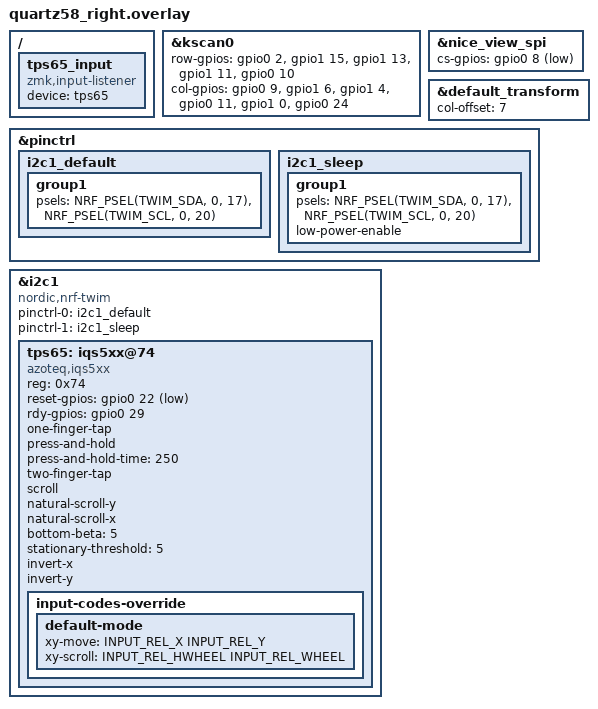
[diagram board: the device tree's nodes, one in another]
/*
 * Copyright (c) 2020 Pete Johanson
 *
 * SPDX-License-Identifier: MIT
 */

#include <dt-bindings/zmk/matrix_transform.h>
#include <dt-bindings/input/input-event-codes.h>
#include "quartz58.dtsi"

&kscan0 {
    row-gpios
        = <&gpio0 2  (GPIO_ACTIVE_HIGH | GPIO_PULL_DOWN)>
        , <&gpio1 15  (GPIO_ACTIVE_HIGH | GPIO_PULL_DOWN)>
        , <&gpio1 13 (GPIO_ACTIVE_HIGH | GPIO_PULL_DOWN)>
        , <&gpio1 11 (GPIO_ACTIVE_HIGH | GPIO_PULL_DOWN)>
        , <&gpio0 10 (GPIO_ACTIVE_HIGH | GPIO_PULL_DOWN)>
    ;

    col-gpios
        = <&gpio0 9  GPIO_ACTIVE_HIGH>
        , <&gpio1 6  GPIO_ACTIVE_HIGH>
        , <&gpio1 4  GPIO_ACTIVE_HIGH>
        , <&gpio0 11 GPIO_ACTIVE_HIGH>
        , <&gpio1 0  GPIO_ACTIVE_HIGH>
        , <&gpio0 24 GPIO_ACTIVE_HIGH>
    ;
};

&nice_view_spi {
    cs-gpios = <&gpio0 8 GPIO_ACTIVE_LOW>;
};

&default_transform {
    col-offset = <7>;
};

/ {

    // TPS65 trackpad input listener (right side only)
    tps65_input: tps65_input {
        compatible = "zmk,input-listener";
        device = <&tps65>;
    };
    
//     physical_layout0: physical_layout_0 {
//         compatible = "zmk,physical-layout";
//         display-name = "quartz58_right";
//         transform = <&default_transform>;
//         kscan = <&kscan0>;
//         keys  //                     w   h    x    y     rot    rx    ry
//             = <&key_physical_attrs 100 100  100    0       0     0     0>
//             , <&key_physical_attrs 100 100  200    0       0     0     0>
//             , <&key_physical_attrs 100 100  300    0       0     0     0>
//             , <&key_physical_attrs 100 100  400    0       0     0     0>
//             , <&key_physical_attrs 100 100  500    0       0     0     0>
//             , <&key_physical_attrs 100 100  600    0       0     0     0>
//             , <&key_physical_attrs 100 100  100  100       0     0     0>
//             , <&key_physical_attrs 100 100  200  100       0     0     0>
//             , <&key_physical_attrs 100 100  300  100       0     0     0>
//             , <&key_physical_attrs 100 100  400  100       0     0     0>
//             , <&key_physical_attrs 100 100  500  100       0     0     0>
//             , <&key_physical_attrs 100 100  600  100       0     0     0>
//             , <&key_physical_attrs 100 100    0  200       0     0     0>
//             , <&key_physical_attrs 100 100  100  200       0     0     0>
//             , <&key_physical_attrs 100 100  200  200       0     0     0>
//             , <&key_physical_attrs 100 100  300  200       0     0     0>
//             , <&key_physical_attrs 100 100  400  200       0     0     0>
//             , <&key_physical_attrs 100 100  500  200       0     0     0>
//             , <&key_physical_attrs 100 100  600  200       0     0     0>
//             , <&key_physical_attrs 100 100  100  300       0     0     0>
//             , <&key_physical_attrs 100 100  200  300       0     0     0>
//             , <&key_physical_attrs 100 100  300  300       0     0     0>
//             , <&key_physical_attrs 100 100  400  300       0     0     0>
//             , <&key_physical_attrs 100 100  500  300       0     0     0>
//             , <&key_physical_attrs 100 100  600  300       0     0     0>
//             , <&key_physical_attrs 100 100  100  400       0     0     0>
//             , <&key_physical_attrs 100 100  200  400       0     0     0>
//             , <&key_physical_attrs 100 100  300  400       0     0     0>
//             , <&key_physical_attrs 100 100  400  400       0     0     0>
//             ;
//     };
};

// Configure I2C1 on actual trackpad pins (P0.17=SDA, P0.20=SCL)
&pinctrl {
    i2c1_default: i2c1_default {
        group1 {
            psels = <NRF_PSEL(TWIM_SDA, 0, 17)>,
                    <NRF_PSEL(TWIM_SCL, 0, 20)>;
        };
    };

    i2c1_sleep: i2c1_sleep {
        group1 {
            psels = <NRF_PSEL(TWIM_SDA, 0, 17)>,
                    <NRF_PSEL(TWIM_SCL, 0, 20)>;
            low-power-enable;
        };
    };
};

// TPS65 trackpad on I2C1 (serial pins)
&i2c1 {
    status = "okay";
    compatible = "nordic,nrf-twim";
    pinctrl-0 = <&i2c1_default>;
    pinctrl-1 = <&i2c1_sleep>;
    pinctrl-names = "default", "sleep";
    
    tps65: iqs5xx@74 {
        status = "okay";
        compatible = "azoteq,iqs5xx";
        reg = <0x74>;
        
        reset-gpios = <&gpio0 22 GPIO_ACTIVE_LOW>;
        rdy-gpios = <&gpio0 29 GPIO_ACTIVE_HIGH>;

        one-finger-tap;
        press-and-hold;
        press-and-hold-time = <250>;
        two-finger-tap;

        scroll;
        natural-scroll-y;
        natural-scroll-x;

        bottom-beta = <5>;
        stationary-threshold = <5>;

        invert-x;
        invert-y;
        
        input-codes-override {
            default-mode {
                xy-move = <INPUT_REL_X INPUT_REL_Y>;
                xy-scroll = <INPUT_REL_HWHEEL INPUT_REL_WHEEL>;
            };
        };
    };
};
